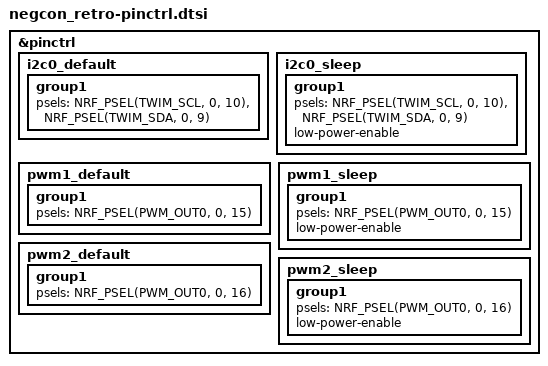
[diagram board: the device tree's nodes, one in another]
&pinctrl {
	i2c0_default: i2c0_default {
		group1 {
			psels = <NRF_PSEL(TWIM_SCL, 0, 10)>,
				<NRF_PSEL(TWIM_SDA, 0, 9)>;
		};
	};

	i2c0_sleep: i2c0_sleep {
		group1 {
			psels = <NRF_PSEL(TWIM_SCL, 0, 10)>,
				<NRF_PSEL(TWIM_SDA, 0, 9)>;
			low-power-enable;
		};
	};

	pwm1_default: pwm1_default {
		group1 {
			psels = <NRF_PSEL(PWM_OUT0, 0, 15)>;
		};
	};

	pwm1_sleep: pwm1_sleep {
		group1 {
			psels = <NRF_PSEL(PWM_OUT0, 0, 15)>;
			low-power-enable;
		};
	};

	pwm2_default: pwm2_default {
		group1 {
			psels = <NRF_PSEL(PWM_OUT0, 0, 16)>;
		};
	};

	pwm2_sleep: pwm2_sleep {
		group1 {
			psels = <NRF_PSEL(PWM_OUT0, 0, 16)>;
			low-power-enable;
		};
	};
};
